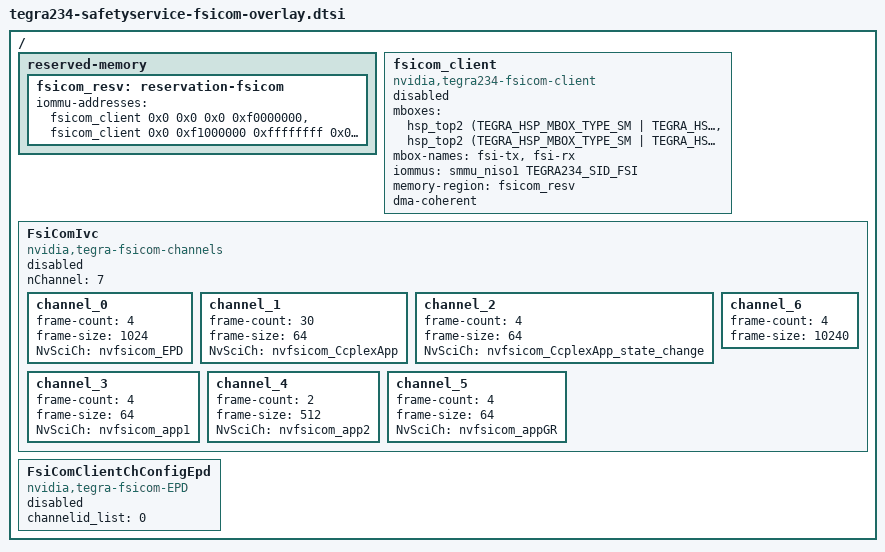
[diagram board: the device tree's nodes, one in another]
// SPDX-License-Identifier: GPL-2.0
// Copyright (c) 2023, NVIDIA CORPORATION & AFFILIATES.  All rights reserved.

#include <dt-bindings/mailbox/tegra186-hsp.h>
#include <dt-bindings/memory/tegra234-mc.h>

/ {
	fragment-fsicom@0 {
		target-path = "/";
		__overlay__ {
			reserved-memory {
				fsicom_resv: reservation-fsicom {
					iommu-addresses = <&fsicom_client 0x0 0x0 0x0 0xf0000000>,
						<&fsicom_client 0x0 0xf1000000 0xffffffff 0x0effffff>;
				};
			};

			fsicom_client: fsicom_client {
				compatible = "nvidia,tegra234-fsicom-client";
				mboxes =
					<&hsp_top2 (TEGRA_HSP_MBOX_TYPE_SM | TEGRA_HSP_MBOX_TYPE_SM_128BIT) TEGRA_HSP_SM_TX(2)>,
					<&hsp_top2 (TEGRA_HSP_MBOX_TYPE_SM | TEGRA_HSP_MBOX_TYPE_SM_128BIT) TEGRA_HSP_SM_RX(1)>;
				mbox-names = "fsi-tx", "fsi-rx";
				iommus = <&smmu_niso1 TEGRA234_SID_FSI>;
				memory-region = <&fsicom_resv>;
				dma-coherent;
				status = "disabled";
			};

			FsiComIvc {
				compatible = "nvidia,tegra-fsicom-channels";
				status = "disabled";
				nChannel = <7>;
				channel_0 {
					frame-count = <4>;
					frame-size = <1024>;
					NvSciCh = "nvfsicom_EPD";
				};

				channel_1 {
					frame-count = <30>;
					frame-size = <64>;
					NvSciCh = "nvfsicom_CcplexApp";
				};

				channel_2 {
					frame-count = <4>;
					frame-size = <64>;
					NvSciCh = "nvfsicom_CcplexApp_state_change";
				};

				channel_3 {
					frame-count = <4>;
					frame-size = <64>;
					NvSciCh = "nvfsicom_app1";
				};

				channel_4 {
					frame-count = <2>;
					frame-size = <512>;
					NvSciCh = "nvfsicom_app2";
				};

				channel_5 {
					frame-count = <4>;
					frame-size = <64>;
					NvSciCh = "nvfsicom_appGR";
				};

				channel_6 {
					frame-count = <4>;
					frame-size = <10240>;
				};
			};

			FsiComClientChConfigEpd {
				compatible = "nvidia,tegra-fsicom-EPD";
				status = "disabled";
				channelid_list = <0>;
			};
		};
	};
};
